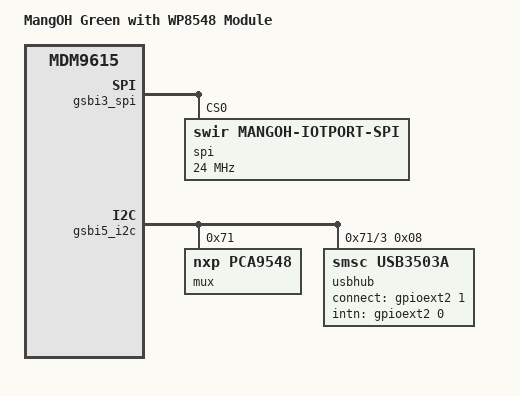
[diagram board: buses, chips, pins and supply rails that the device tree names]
#include <dt-bindings/input/input.h>
#include "qcom-mdm9615-wp8548.dtsi"
#include <dt-bindings/interrupt-controller/irq.h>
#include <dt-bindings/gpio/gpio.h>
/ {
	model = "MangOH Green with WP8548 Module";
	compatible = "swir,mangoh-green-wp8548", "swir,wp8548", "qcom,mdm9615";
	aliases {
		spi0 = &gsbi3_spi;
		serial0 = &gsbi4_serial;
		serial1 = &gsbi5_serial;
		i2c0 = &gsbi5_i2c;
		mmc0 = &sdcc1;
	};
	chosen {
		stdout-path = "serial1:115200n8";
	};
};
&msmgpio {
	gpioext1_pins: gpioext1-state {
		gpioext1-pins {
			pins = "gpio2";
			function = "gpio";
			bias-disable;
		};
	};
	sdc_cd_pins: sdc-cd-state {
		sdc-cd-pins {
			pins = "gpio42";
			function = "gpio";
			drive-strength = <2>;
			bias-pull-up;
		};
	};
};
&gsbi3_spi {
	spi@0 {
		compatible = "swir,mangoh-iotport-spi";
		spi-max-frequency = <24000000>;
		reg = <0>;
	};
};
&gsbi5_i2c {
	mux@71 {
		compatible = "nxp,pca9548";
		#address-cells = <1>;
		#size-cells = <0>;
		reg = <0x71>;
		i2c_iot0: i2c@0 {
			#address-cells = <1>;
			#size-cells = <0>;
			reg = <0>;
		};
		i2c_iot1: i2c@1 {
			#address-cells = <1>;
			#size-cells = <0>;
			reg = <1>;
		};
		i2c_iot2: i2c@2 {
			#address-cells = <1>;
			#size-cells = <0>;
			reg = <2>;
		};
		i2c@3 {
			#address-cells = <1>;
			#size-cells = <0>;
			reg = <3>;
			usbhub: hub@8 {
				compatible = "smsc,usb3503a";
				reg = <0x8>;
				connect-gpios = <&gpioext2 1 GPIO_ACTIVE_HIGH>;
				intn-gpios = <&gpioext2 0 GPIO_ACTIVE_HIGH>;
				initial-mode = <1>;
			};
		};
		i2c@4 {
			#address-cells = <1>;
			#size-cells = <0>;
			reg = <4>;
			gpioext0: pinctrl@3e {
				#gpio-cells = <2>;
				#interrupt-cells = <2>;
				compatible = "semtech,sx1509q";
				reg = <0x3e>;
				interrupt-parent = <&gpioext1>;
				interrupts = <0 IRQ_TYPE_EDGE_FALLING>;
				semtech,probe-reset;
				gpio-controller;
				interrupt-controller;
			};
		};
		i2c@5 {
			#address-cells = <1>;
			#size-cells = <0>;
			reg = <5>;
			gpioext1: pinctrl@3f {
				pinctrl-0 = <&gpioext1_pins>;
				pinctrl-names = "default";
				#gpio-cells = <2>;
				#interrupt-cells = <2>;
				compatible = "semtech,sx1509q";
				reg = <0x3f>;
				interrupt-parent = <&msmgpio>;
				interrupts = <0 IRQ_TYPE_EDGE_FALLING>;
				semtech,probe-reset;
				gpio-controller;
				interrupt-controller;
			};
		};
		i2c@6 {
			#address-cells = <1>;
			#size-cells = <0>;
			reg = <6>;
			gpioext2: pinctrl@70 {
				#gpio-cells = <2>;
				#interrupt-cells = <2>;
				compatible = "semtech,sx1509q";
				reg = <0x70>;
				interrupt-parent = <&gpioext1>;
				interrupts = <14 IRQ_TYPE_EDGE_FALLING>;
				semtech,probe-reset;
				gpio-controller;
				interrupt-controller;
			};
		};
		i2c@7 {
			#address-cells = <1>;
			#size-cells = <0>;
			reg = <7>;
		};
	};
};
&sdcc1 {
	pinctrl-0 = <&sdc_cd_pins>;
	pinctrl-names = "default";
	disable-wp;
	cd-gpios = <&msmgpio 42 GPIO_ACTIVE_LOW>;  
};
